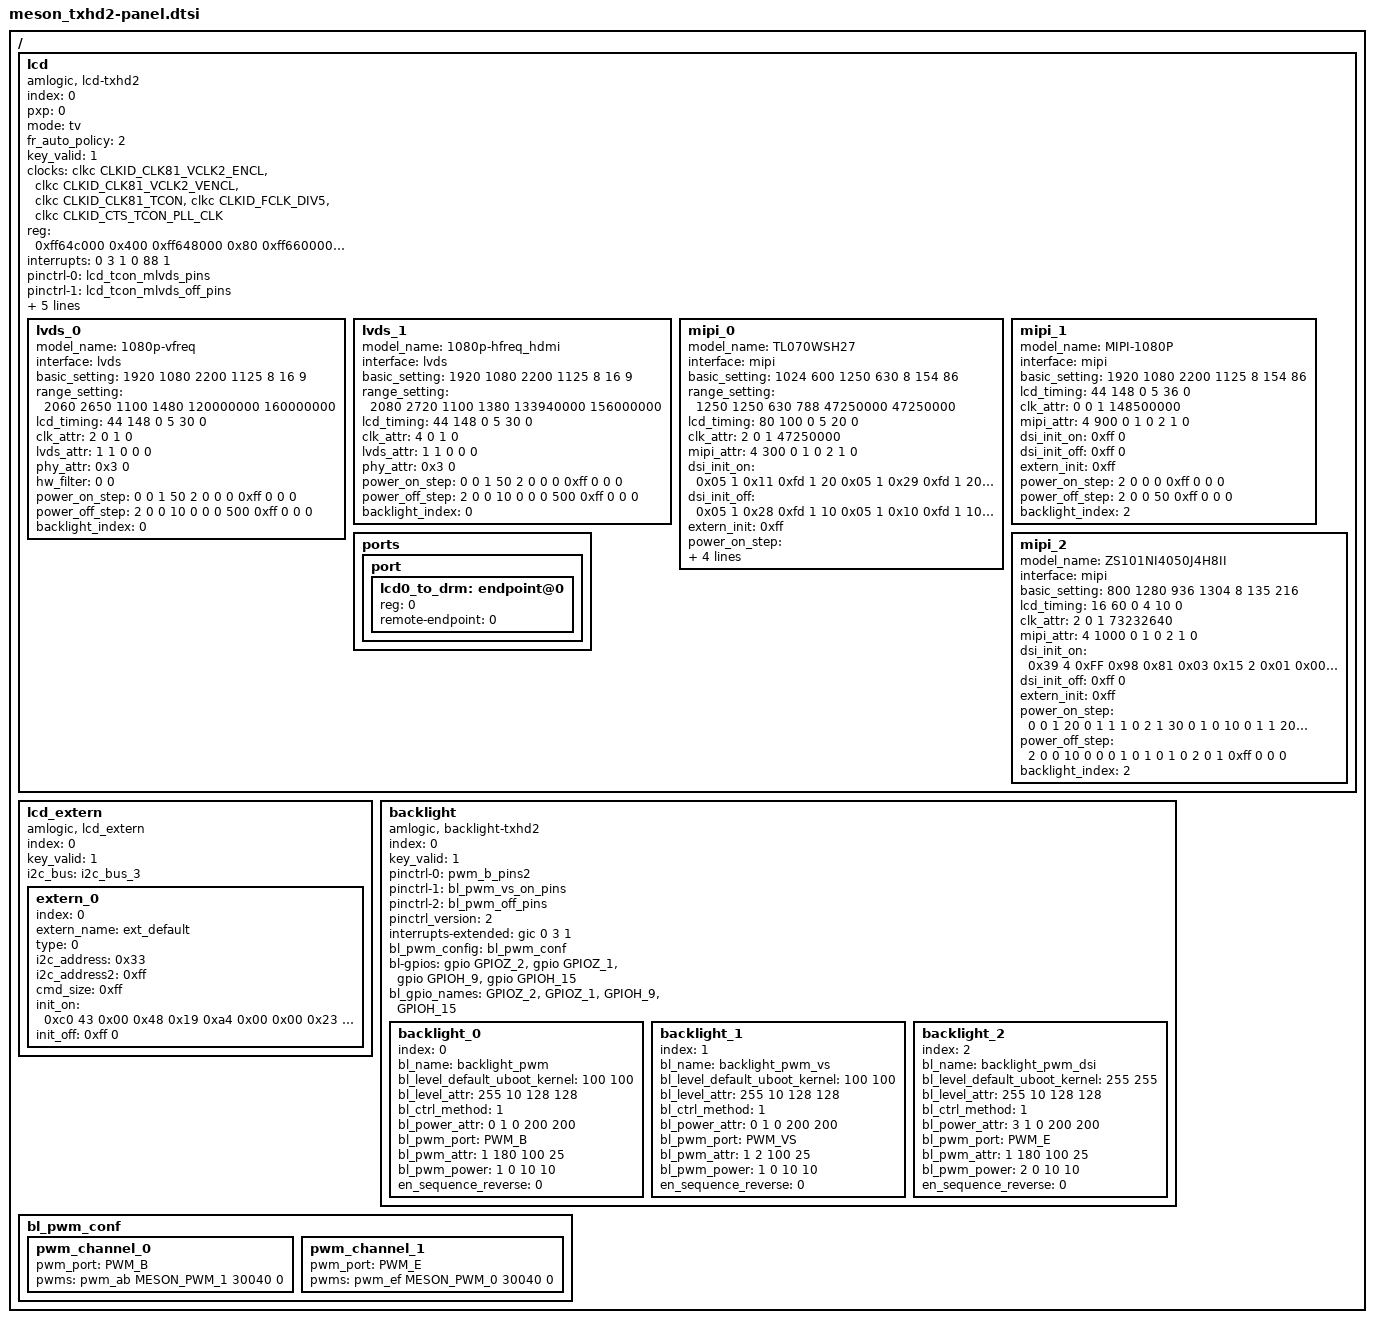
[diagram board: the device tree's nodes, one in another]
// SPDX-License-Identifier: (GPL-2.0+ OR MIT)
/*
 * Copyright (c) 2019 Amlogic, Inc. All rights reserved.
 */

/ {
	lcd:lcd {
		compatible = "amlogic, lcd-txhd2";
		status = "okay";
		index = <0>;
		pxp = <0>;
		mode = "tv";
		fr_auto_policy = <2>; /* 0=disable, 1=60/50hz, 2=60/50/48hz */
		key_valid = <1>;
		clocks = <&clkc CLKID_CLK81_VCLK2_ENCL
			&clkc CLKID_CLK81_VCLK2_VENCL
			&clkc CLKID_CLK81_TCON
			&clkc CLKID_FCLK_DIV5
			&clkc CLKID_CTS_TCON_PLL_CLK>;
		clock-names = "encl_top_gate",
			"encl_int_gate",
			"tcon_gate",
			"fclk_div5",
			"clk_tcon";
		reg = <0xff64c000 0x400 /* dsi_host */
			0xff648000 0x80    /* dsi_phy */
			0xff660000 0xd000  /* tcon */
			0xff634400 0x300    /* periphs */
			0xffd01000 0xa0    /* reset */
			0xff648000 0x100>;  /* combo_dphy */
		interrupts = <0 3 1
			0 88 1>;
		interrupt-names = "vsync","tcon";
		pinctrl-names = "tcon_mlvds","tcon_mlvds_off";
		pinctrl-0 = <&lcd_tcon_mlvds_pins>;
		pinctrl-1 = <&lcd_tcon_mlvds_off_pins>;
		memory-region = <&lcd_tcon_reserved>;

		/* power type:(0=cpu_gpio, 2=signal, 3=extern, 0xff=ending) */
		/* power index:(gpios_index, or extern_index, 0xff=invalid) */
		/* power value:(0=output low, 1=output high, 2=input) */
		/* power delay:(unit in ms) */

		lcd_cpu-gpios = <&gpio GPIOZ_3 GPIO_ACTIVE_HIGH
					&gpio GPIOH_14 GPIO_ACTIVE_HIGH
					&gpio GPIOH_10 GPIO_ACTIVE_HIGH>;
		lcd_cpu_gpio_names = "GPIOZ_3", "GPIOH_14", "GPIOH_10";

		lvds_0{
			model_name = "1080p-vfreq";
			interface = "lvds"; /*lcd_interface(lvds, vbyone)*/
			basic_setting = <
				1920 1080 /*h_active, v_active*/
				2200 1125 /*h_period, v_period*/
				8      /*lcd_bits */
				16 9>; /*screen_widht, screen_height*/
			range_setting = <
				2060 2650  /*h_period_min,max*/
				1100 1480  /*v_period_min,max*/
				120000000 160000000>; /*pclk_min,max*/
			lcd_timing = <
				44 148 0  /*hs_width, hs_bp, hs_pol*/
				5  30 0>; /*vs_width, vs_bp, vs_pol*/
			clk_attr = <
				2 /*fr_adj_type
				   *(0=clk, 1=htotal, 2=vtotal, 3=auto_range,
				   * 4=hdmi_mode)
				   */
				0 /*clk_ss_level*/
				1 /*clk_auto_generate*/
				0>; /*pixel_clk(unit in Hz)*/
			lvds_attr = <
				1  /*lvds_repack*/
				1  /*dual_port*/
				0  /*pn_swap*/
				0  /*port_swap*/
				0>; /*lane_reverse*/
			phy_attr=<0x3 0>; /*vswing_level, preem_level*/
			hw_filter=<0 0>;  /* filter_time, filter_cnt*/

			/* power step: type, index, value, delay(ms) */
			power_on_step = <
				0 0 1 50   /*panel power*/
				2 0 0 0   /*signal enable*/
				0xff 0 0 0>; /*ending*/
			power_off_step = <
				2 0 0 10  /*signal disable*/
				0 0 0 500   /*panel power*/
				0xff 0 0 0>; /*ending*/
			backlight_index = <0>;
		};
		lvds_1{
			model_name = "1080p-hfreq_hdmi";
			interface = "lvds"; /*lcd_interface(lvds, vbyone)*/
			basic_setting = <
				1920 1080 /*h_active, v_active*/
				2200 1125 /*h_period, v_period*/
				8      /*lcd_bits*/
				16 9>; /*screen_widht, screen_height*/
			range_setting = <
				2080 2720 /*h_period min, max*/
				1100 1380 /*v_period min, max*/
				133940000 156000000>; /*pclk_min, max*/
			lcd_timing = <
				44 148 0   /*hs_width, hs_bp, hs_pol*/
				5  30  0>; /*vs_width, vs_bp, vs_pol*/
			clk_attr = <
				4 /*fr_adj_type
				   *(0=clk, 1=htotal, 2=vtotal, 3=auto_range,
				   * 4=hdmi_mode)
				   */
				0 /*clk_ss_level */
				1 /*clk_auto_generate*/
				0>; /*pixel_clk(unit in Hz)*/
			lvds_attr = <
				1 /*lvds_repack*/
				1 /*dual_port*/
				0 /*pn_swap*/
				0 /*port_swap*/
				0>; /*lane_reverse*/
			phy_attr=<0x3 0>; /*vswing_level, preem_level*/

			/* power step: type, index, value, delay(ms) */
			power_on_step = <
				0 0 1 50   /*panel power*/
				2 0 0 0   /*signal enable*/
				0xff 0 0 0>; /*ending*/
			power_off_step = <
				2 0 0 10  /*signal disable*/
				0 0 0 500   /*panel power*/
				0xff 0 0 0>; /*ending*/
			backlight_index = <0>;
		};

		mipi_0{
			model_name = "TL070WSH27";
			interface = "mipi";
			basic_setting = <1024 600 /*h_active, v_active*/
				1250 630 /*h_period, v_period*/
				8 /*lcd_bits*/
				154 86>; /*screen_widht, screen_height*/
			range_setting = <
				1250 1250 /*h_period min, max*/
				630 788 /*v_period min, max*/
				47250000 47250000>; /*pclk_min, max*/
			lcd_timing = <80 100 0 /*hs_width, hs_bp, hs_pol*/
				5 20 0>; /*vs_width, vs_bp, vs_pol*/
			clk_attr = <2 /*fr_adj_type(0=clk, 1=htotal, 2=vtotal)*/
				0 /*clk_ss_level */
				1 /*clk_auto_generate*/
				47250000>; /*pixel_clk(unit in Hz)*/
			mipi_attr = <4 /*lane_num*/
				300 /*bit_rate_max(MHz)*/
				0 /*factor(*100, default 0 for auto)*/
				1 /*operation_mode_init(0=video, 1=command)*/
				0 /*operation_mode_display(0=video, 1=command)*/
				2 /*
				   *video_mode_type
				   *(0=sync_pulse,1=sync_event,2=burst)
				   */
				1 /*clk_always_hs(0=disable,1=enable)*/
				0>; /*phy_switch(0=auto,1=standard,2=slow)*/

			/* dsi_init: data_type, num, data... */
			dsi_init_on = <0x05 1 0x11
					0xfd 1 20     /*delay(ms)*/
					0x05 1 0x29
					0xfd 1 20     /*delay(ms)*/
					0xff 0>; /*ending*/
			dsi_init_off = <0x05 1 0x28
					0xfd 1 10     /*delay(ms)*/
					0x05 1 0x10
					0xfd 1 10     /*delay(ms)*/
					0xff 0>; /*ending*/
			extern_init = <0xff>; /*0xff for invalid*/

			/* power step: type, index, value, delay(ms) */
			power_on_step = <
				0 0 1 100
				0 1 0 10
				0 1 1 20
				2 0 0 0
				0xff 0 0 0>; /*ending*/
			power_off_step = <
				2 0 0 50
				0 1 0 10
				0 0 0 100
				0xff 0 0 0>; /*ending*/
			backlight_index = <2>;
		};

		mipi_1{
			model_name = "MIPI-1080P";
			interface = "mipi";
			basic_setting = <1920 1080 /*h_active, v_active*/
				2200 1125 /*h_period, v_period*/
				8 /*lcd_bits*/
				154 86>; /*screen_widht, screen_height*/
			lcd_timing = <44 148 0 /*hs_width, hs_bp, hs_pol*/
				5 36 0>; /*vs_width, vs_bp, vs_pol*/
			clk_attr = <0 /*fr_adj_type(0=clk, 1=htotal, 2=vtotal)*/
				0 /*clk_ss_level */
				1 /*clk_auto_generate*/
				148500000>; /*pixel_clk(unit in Hz)*/
			mipi_attr = <4 /*lane_num*/
				900 /*bit_rate_max(MHz)*/
				0 /*factor(*100, default 0 for auto)*/
				1 /*operation_mode_init(0=video, 1=command)*/
				0 /*operation_mode_display(0=video, 1=command)*/
				2 /*
				   *video_mode_type
				   *(0=sync_pulse,1=sync_event,2=burst)
				   */
				1 /*clk_always_hs(0=disable,1=enable)*/
				0>; /*phy_switch(0=auto,1=standard,2=slow)*/

			/* dsi_init: data_type, num, data... */
			dsi_init_on = <0xff 0>; /*ending*/
			dsi_init_off = <0xff 0>; /*ending*/
			extern_init = <0xff>; /*0xff for invalid*/

			/* power step: type, index, value, delay(ms) */
			power_on_step = <
				2 0 0 0
				0xff 0 0 0>; /*ending*/
			power_off_step = <
				2 0 0 50
				0xff 0 0 0>; /*ending*/
			backlight_index = <2>;
		};

		mipi_2{
			model_name = "ZS101NI4050J4H8II";
			interface = "mipi";
			basic_setting = <800 1280 /*h_active, v_active*/
				936 1304 /*h_period, v_period*/
				8 /*lcd_bits*/
				135 216>; /*screen_widht, screen_height*/
			lcd_timing = <16 60 0 /*hs_width, hs_bp, hs_pol*/
				4 10 0>; /*vs_width, vs_bp, vs_pol*/
			clk_attr = <2 /*fr_adj_type(0=clk, 1=htotal, 2=vtotal)*/
				0 /*clk_ss_level */
				1 /*clk_auto_generate*/
				73232640>; /*pixel_clk(unit in Hz)*/
			mipi_attr = <4 /*lane_num*/
				1000 /*bit_rate_max(MHz)*/
				0 /*factor(*100, default 0 for auto)*/
				1 /*operation_mode_init(0=video, 1=command)*/
				0 /*operation_mode_display(0=video, 1=command)*/
				2 /*
				   *video_mode_type
				   *(0=sync_pulse,1=sync_event,2=burst)
				   */
				1 /*clk_always_hs(0=disable,1=enable)*/
				0>; /*phy_switch(0=auto,1=standard,2=slow)*/

			/* dsi_init: data_type, num, data... */
			dsi_init_on = <
					0x39 4 0xFF 0x98 0x81 0x03

					0x15 2 0x01 0x00
					0x15 2 0x02 0x00
					0x15 2 0x03 0x53
					0x15 2 0x04 0x53
					0x15 2 0x05 0x13
					0x15 2 0x06 0x04
					0x15 2 0x07 0x02
					0x15 2 0x08 0x02
					0x15 2 0x09 0x00
					0x15 2 0x0a 0x00
					0x15 2 0x0b 0x00
					0x15 2 0x0c 0x00
					0x15 2 0x0d 0x00
					0x15 2 0x0e 0x00
					0x15 2 0x0f 0x00
					0x15 2 0x10 0x00
					0x15 2 0x11 0x00
					0x15 2 0x12 0x00
					0x15 2 0x13 0x00
					0x15 2 0x14 0x00

					0x15 2 0x15 0x05
					0x15 2 0x16 0x05

					0x15 2 0x17 0x03
					0x15 2 0x18 0x03

					0x15 2 0x19 0x00
					0x15 2 0x1a 0x00
					0x15 2 0x1b 0x00
					0x15 2 0x1c 0x00
					0x15 2 0x1d 0x00
					0x15 2 0x1e 0xc0
					0x15 2 0x1f 0x00
					0x15 2 0x20 0x02
					0x15 2 0x21 0x09
					0x15 2 0x22 0x00
					0x15 2 0x23 0x00
					0x15 2 0x24 0x00
					0x15 2 0x25 0x00
					0x15 2 0x26 0x00
					0x15 2 0x27 0x00
					0x15 2 0x28 0x55
					0x15 2 0x29 0x03
					0x15 2 0x2a 0x00
					0x15 2 0x2b 0x00
					0x15 2 0x2c 0x00
					0x15 2 0x2d 0x00
					0x15 2 0x2e 0x00
					0x15 2 0x2f 0x00
					0x15 2 0x30 0x00
					0x15 2 0x31 0x00
					0x15 2 0x32 0x00
					0x15 2 0x33 0x00
					0x15 2 0x34 0x00
					0x15 2 0x35 0x00
					0x15 2 0x36 0x00
					0x15 2 0x37 0x00
					0x15 2 0x38 0x3C
					0x15 2 0x39 0x00
					0x15 2 0x3a 0x00
					0x15 2 0x3b 0x00
					0x15 2 0x3c 0x00
					0x15 2 0x3d 0x00
					0x15 2 0x3e 0x00
					0x15 2 0x3f 0x00
					0x15 2 0x40 0x00
					0x15 2 0x41 0x00
					0x15 2 0x42 0x00
					0x15 2 0x43 0x00
					0x15 2 0x44 0x00

					0x15 2 0x50 0x01
					0x15 2 0x51 0x23
					0x15 2 0x52 0x45
					0x15 2 0x53 0x67
					0x15 2 0x54 0x89
					0x15 2 0x55 0xab
					0x15 2 0x56 0x01
					0x15 2 0x57 0x23
					0x15 2 0x58 0x45
					0x15 2 0x59 0x67
					0x15 2 0x5a 0x89
					0x15 2 0x5b 0xab
					0x15 2 0x5c 0xcd
					0x15 2 0x5d 0xef

					0x15 2 0x5e 0x01
					0x15 2 0x5f 0x0A
					0x15 2 0x60 0x02
					0x15 2 0x61 0x02
					0x15 2 0x62 0x08
					0x15 2 0x63 0x15
					0x15 2 0x64 0x14
					0x15 2 0x65 0x02
					0x15 2 0x66 0x11
					0x15 2 0x67 0x10
					0x15 2 0x68 0x02
					0x15 2 0x69 0x0F
					0x15 2 0x6a 0x0E
					0x15 2 0x6b 0x02
					0x15 2 0x6c 0x0D
					0x15 2 0x6d 0x0C
					0x15 2 0x6e 0x06
					0x15 2 0x6f 0x02
					0x15 2 0x70 0x02
					0x15 2 0x71 0x02
					0x15 2 0x72 0x02
					0x15 2 0x73 0x02
					0x15 2 0x74 0x02

					0x15 2 0x75 0x0A
					0x15 2 0x76 0x02
					0x15 2 0x77 0x02
					0x15 2 0x78 0x06
					0x15 2 0x79 0x15
					0x15 2 0x7a 0x14
					0x15 2 0x7b 0x02
					0x15 2 0x7c 0x10
					0x15 2 0x7d 0x11
					0x15 2 0x7e 0x02
					0x15 2 0x7f 0x0C
					0x15 2 0x80 0x0D
					0x15 2 0x81 0x02
					0x15 2 0x82 0x0E
					0x15 2 0x83 0x0F
					0x15 2 0x84 0x08
					0x15 2 0x85 0x02
					0x15 2 0x86 0x02
					0x15 2 0x87 0x02
					0x15 2 0x88 0x02
					0x15 2 0x89 0x02
					0x15 2 0x8A 0x02

					0x39 4 0xFF 0x98 0x81 0x04

					0x15 2 0x3B 0xC0
					0x15 2 0x6C 0x15

					0x15 2 0x6E 0x30
					0x15 2 0x6F 0x33
					0x15 2 0x8D 0x1F

					0x15 2 0x3A 0x24
					0x15 2 0x35 0x1F

					0x15 2 0x87 0xBA
					0x15 2 0x26 0x76
					0x15 2 0xB2 0xD1
					0x15 2 0xB5 0x07
					0x15 2 0x88 0x0B
					0x15 2 0x21 0x30

					0x39 4 0xFF 0x98 0x81 0x01

					0x15 2 0x22 0x0A
					0x15 2 0x31 0x09
					0x15 2 0x40 0x33
					0x15 2 0x42 0x44
					0x15 2 0x53 0x2E
					0x15 2 0x55 0x88
					0x15 2 0x50 0x95
					0x15 2 0x51 0x95
					0x15 2 0x60 0x43

					0x15 2 0x2E 0xC8

					0x15 2 0xA0 0x0F
					0x15 2 0xA1 0x1D
					0x15 2 0xA2 0x2A
					0x15 2 0xA3 0x14
					0x15 2 0xA4 0x16
					0x15 2 0xA5 0x29
					0x15 2 0xA6 0x1D
					0x15 2 0xA7 0x1E
					0x15 2 0xA8 0x83
					0x15 2 0xA9 0x1E
					0x15 2 0xAA 0x2B
					0x15 2 0xAB 0x6F
					0x15 2 0xAC 0x18
					0x15 2 0xAD 0x17
					0x15 2 0xAE 0x4C
					0x15 2 0xAF 0x22
					0x15 2 0xB0 0x27
					0x15 2 0xB1 0x4D
					0x15 2 0xB2 0x5C
					0x15 2 0xB3 0x2B

					0x15 2 0xC0 0x0F
					0x15 2 0xC1 0x1D
					0x15 2 0xC2 0x2A
					0x15 2 0xC3 0x14
					0x15 2 0xC4 0x16
					0x15 2 0xC5 0x29
					0x15 2 0xC6 0x1D
					0x15 2 0xC7 0x1E
					0x15 2 0xC8 0x83
					0x15 2 0xC9 0x1E
					0x15 2 0xCA 0x2B
					0x15 2 0xCB 0x6F
					0x15 2 0xCC 0x18
					0x15 2 0xCD 0x17
					0x15 2 0xCE 0x4C
					0x15 2 0xCF 0x22
					0x15 2 0xD0 0x27
					0x15 2 0xD1 0x4D
					0x15 2 0xD2 0x5C
					0x15 2 0xD3 0x2B
					0x39 4 0xFF 0x98 0x81 0x00

					0x15 2 0x35 0x00

					0x05 1 0x11
					0xfd 1 120
					0x05 1 0x29
					0xfd 1 20
					0xff 0>; /*ending*/
			dsi_init_off = <0xff 0>; /*ending*/
			extern_init = <0xff>; /*0xff for invalid*/

			/* power step: type, index, value, delay(ms) */
			power_on_step = <
				0 0 1 20
				0 1 1 1
				0 2 1 30
				0 1 0 10
				0 1 1 20
				2 0 0 0
				0xff 0 0 0>; /*ending*/
			power_off_step = <
				2 0 0 10
				0 0 0 1
				0 1 0 1
				0 2 0 1
				0xff 0 0 0>; /*ending*/
			backlight_index = <2>;
		};

		ports {
			port {
				#address-cells = <1>;
				#size-cells = <0>;
				lcd0_to_drm: endpoint@0 {
					reg = <0>;
					remote-endpoint = <0>;
				};
			};
		};
	};

	lcd_extern{
		compatible = "amlogic, lcd_extern";
		status = "okay";
		index = <0>;
		key_valid = <1>;
		i2c_bus = "i2c_bus_3";

		extern_0{
			index = <0>;
			extern_name = "ext_default";
			status = "okay";
			type = <0>; /*0=i2c, 1=spi, 2=mipi*/
			i2c_address = <0x33>; /*7bit i2c_addr*/
			i2c_address2 = <0xff>;
			cmd_size = <0xff>; /*dynamic cmd_size*/

			/* init on/off:
			 *  fixed cmd_size: (type, value...);
			 *                  cmd_size include all data.
			 *  dynamic cmd_size: (type, cmd_size, value...);
			 *                    cmd_size include value.
			 */
			/* type: 0x00=cmd with delay(bit[3:0]=1 for address2),
			 *       0xc0=cmd(bit[3:0]=1 for address2),
			 *       0xf0=gpio,
			 *       0xfd=delay,
			 *       0xff=ending
			 */
			/* value: i2c or spi cmd, or gpio index & level */
			/* delay: unit ms */
			init_on = <
				0xc0 43 0x00
					0x48 0x19 0xa4 0x00 0x00 0x23 0xfc 0x66 0xfb 0x2b 0x28 0x00
					0x10 0x10 0x07 0x07 0x3e 0xc3 0xd3 0x33 0xa2 0xde 0x2b 0x02
					0x3d 0x21 0xa1 0xbf 0x1a 0x71 0x33 0x0f 0xd0 0xa1 0x01 0x70
					0x0e 0x1a 0x11 0xb5 0xcd 0xf9
				0xff 0>; /*ending*/
			init_off = <0xff 0>; /*ending*/
		};
	};

	backlight{
		compatible = "amlogic, backlight-txhd2";
		status = "okay";
		index = <0>;
		key_valid = <1>;
		pinctrl-names = "pwm_on","pwm_vs_on",
				"pwm_off";
		pinctrl-0 = <&pwm_b_pins2>;
		pinctrl-1 = <&bl_pwm_vs_on_pins>;
		pinctrl-2 = <&bl_pwm_off_pins>;
		pinctrl_version = <2>; /* for uboot */
		interrupts-extended = <&gic 0 3 1>;
		interrupt-names = "vsync";
		bl_pwm_config = <&bl_pwm_conf>;

		/* pwm port: PWM_A, PWM_B, PWM_C, PWM_D, PWM_E, PWM_F, PWM_VS*/
		/* power index:(point gpios_index, 0xff=invalid) */
		/* power value:(0=output low, 1=output high, 2=input) */
		/* power delay:(unit in ms) */
		bl-gpios = <&gpio GPIOZ_2 GPIO_ACTIVE_HIGH
			&gpio GPIOZ_1 GPIO_ACTIVE_HIGH
			&gpio GPIOH_9 GPIO_ACTIVE_HIGH
			&gpio GPIOH_15 GPIO_ACTIVE_HIGH>;
		bl_gpio_names = "GPIOZ_2","GPIOZ_1", "GPIOH_9","GPIOH_15";

		backlight_0{
			index = <0>;
			bl_name = "backlight_pwm";
			bl_level_default_uboot_kernel = <100 100>;
			bl_level_attr = <255 10 /*max, min*/
				128 128>; /*mid, mid_mapping*/
			bl_ctrl_method = <1>; /*1=pwm,2=pwm_combo,3=ldim*/
			bl_power_attr = <0 /*en_gpio_index*/
				1 0 /*on_value, off_value*/
				200 200>; /*on_delay(ms), off_delay(ms)*/
			bl_pwm_port = "PWM_B";
			bl_pwm_attr = <1 /*pwm_method(0=negative, 1=positvie)*/
				180 /*pwm_freq(pwm:Hz, pwm_vs:multiple of vs)*/
				100 25>; /*duty_max(%), duty_min(%)*/
			bl_pwm_power = <1 0 /*pwm_gpio_index, pwm_gpio_off*/
				10 10>; /*pwm_on_delay(ms), pwm_off_delay(ms)*/
			en_sequence_reverse = <0>; /* 1 for reverse */
		};
		backlight_1{
			index = <1>;
			bl_name = "backlight_pwm_vs";
			bl_level_default_uboot_kernel = <100 100>;
			bl_level_attr = <255 10 /*max, min*/
				128 128>; /*mid, mid_mapping*/
			bl_ctrl_method = <1>; /*1=pwm,2=pwm_combo,3=ldim*/
			bl_power_attr = <0  /*en_gpio_index*/
				1 0 /*on_value, off_value*/
				200 200>; /* on_delay(ms), off_delay(ms)*/
			bl_pwm_port = "PWM_VS";
			bl_pwm_attr = <1 /*pwm_method(0=negative, 1=positvie)*/
				2 /*pwm_freq(pwm:Hz, pwm_vs:multiple of vs)*/
				100 25>; /*duty_max(%), duty_min(%)*/
			bl_pwm_power = <1 0 /*pwm_gpio_index, pwm_gpio_off*/
				10 10>; /*pwm_on_delay(ms), pwm_off_delay(ms)*/
			en_sequence_reverse = <0>; /* 1 for reverse */
		};
		backlight_2{
			index = <2>;
			bl_name = "backlight_pwm_dsi";
			bl_level_default_uboot_kernel = <255 255>;
			bl_level_attr = <255 10 /*max, min*/
				128 128>; /*mid, mid_mapping*/
			bl_ctrl_method = <1>; /*1=pwm,2=pwm_combo,3=ldim*/
			bl_power_attr = <3 /*en_gpio_index*/
				1 0 /*on_value, off_value*/
				200 200>; /*on_delay(ms), off_delay(ms)*/
			bl_pwm_port = "PWM_E";
			bl_pwm_attr = <1 /*pwm_method(0=negative, 1=positvie)*/
				180 /*pwm_freq(pwm:Hz, pwm_vs:multiple of vs)*/
				100 25>; /*duty_max(%), duty_min(%)*/
			bl_pwm_power = <2 0 /*pwm_gpio_index, pwm_gpio_off*/
				10 10>; /*pwm_on_delay(ms), pwm_off_delay(ms)*/
			en_sequence_reverse = <0>; /* 1 for reverse */
		};
	};

	bl_pwm_conf:bl_pwm_conf{
		pwm_channel_0 {
			pwm_port = "PWM_B";
			pwms = <&pwm_ab MESON_PWM_1 30040 0>;
		};
		pwm_channel_1 {
			pwm_port = "PWM_E";
			pwms = <&pwm_ef MESON_PWM_0 30040 0>;
		};
	};
};
